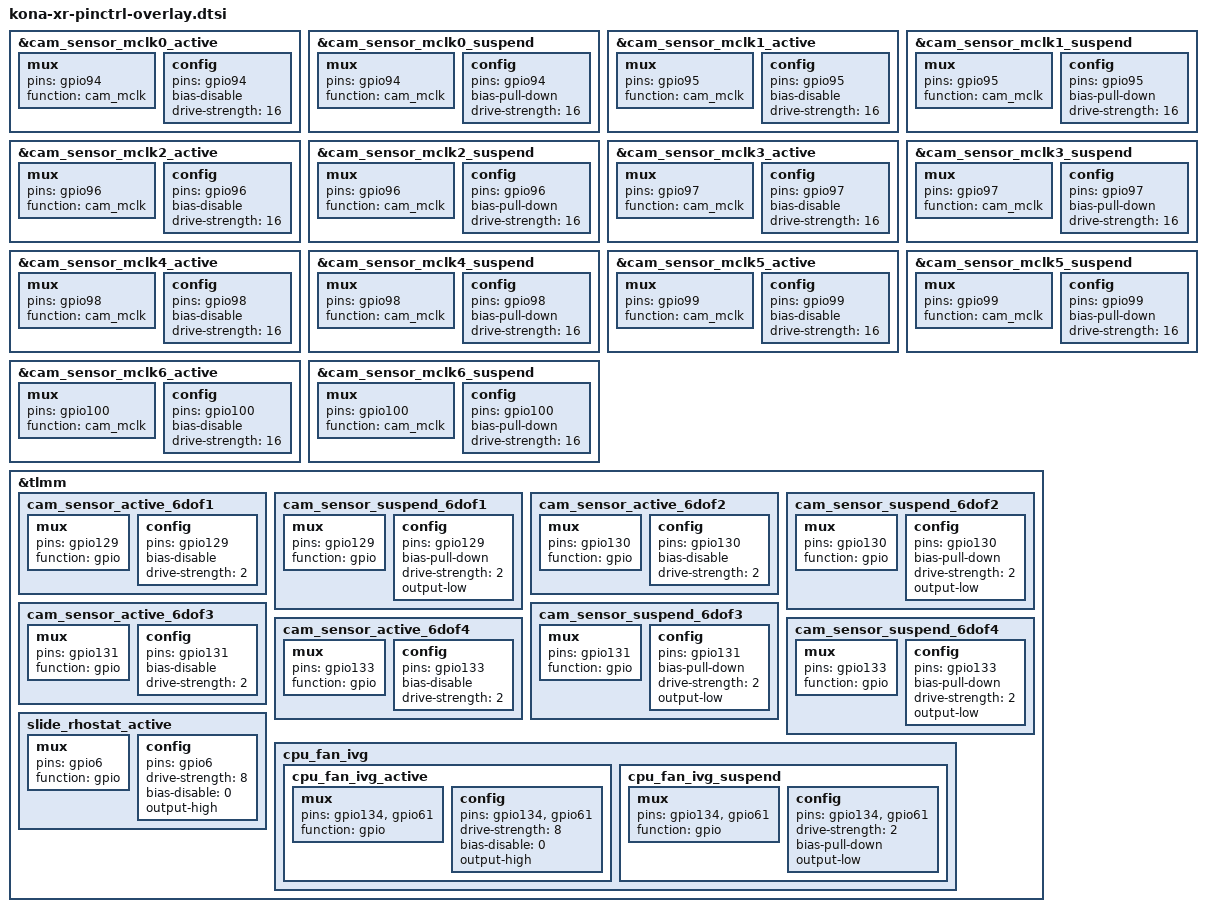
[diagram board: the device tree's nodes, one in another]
&cam_sensor_mclk0_active {
	/* MCLK0 */
	mux {
		pins = "gpio94";
		function = "cam_mclk";
	};

	config {
		pins = "gpio94";
		bias-disable; /* No PULL */
		drive-strength = <16>; /* 2 MA */
	};
};

&cam_sensor_mclk0_suspend {
	/* MCLK0 */
	mux {
		pins = "gpio94";
		function = "cam_mclk";
	};

	config {
		pins = "gpio94";
	bias-pull-down; /* PULL DOWN */
	drive-strength = <16>; /* 2 MA */
	};
};

&cam_sensor_mclk1_active {
	/* MCLK1 */
	mux {
		pins = "gpio95";
		function = "cam_mclk";
	};

	config {
		pins = "gpio95";
		bias-disable; /* No PULL */
		drive-strength = <16>; /* 2 MA */
	};
};

&cam_sensor_mclk1_suspend {
	/* MCLK1 */
	mux {
		pins = "gpio95";
		function = "cam_mclk";
	};

	config {
		pins = "gpio95";
		bias-pull-down; /* PULL DOWN */
		drive-strength = <16>; /* 2 MA */
	};
};

&cam_sensor_mclk2_active {
	/* MCLK2 */
	mux {
		pins = "gpio96";
		function = "cam_mclk";
	};

	config {
		pins = "gpio96";
		bias-disable; /* No PULL */
		drive-strength = <16>; /* 2 MA */
	};
};

&cam_sensor_mclk2_suspend {
	/* MCLK2 */
	mux {
		pins = "gpio96";
		function = "cam_mclk";
	};

	config {
		pins = "gpio96";
		bias-pull-down; /* PULL DOWN */
		drive-strength = <16>; /* 2 MA */
	};
};

&cam_sensor_mclk3_active {
	/* MCLK3 */
	mux {
		pins = "gpio97";
		function = "cam_mclk";
	};

	config {
		pins = "gpio97";
		bias-disable; /* No PULL */
		drive-strength = <16>; /* 2 MA */
	};
};

&cam_sensor_mclk3_suspend {
	/* MCLK3 */
	mux {
		pins = "gpio97";
		function = "cam_mclk";
	};

	config {
		pins = "gpio97";
		bias-pull-down; /* PULL DOWN */
		drive-strength = <16>; /* 2 MA */
	};
};

&cam_sensor_mclk4_active {
	/* MCLK4 */
	mux {
		pins = "gpio98";
		function = "cam_mclk";
	};

	config {
		pins = "gpio98";
	bias-disable; /* No PULL */
	drive-strength = <16>; /* 2 MA */
	};
};

&cam_sensor_mclk4_suspend {
	/* MCLK4 */
	mux {
		pins = "gpio98";
		function = "cam_mclk";
	};

	config {
		pins = "gpio98";
		bias-pull-down; /* PULL DOWN */
		drive-strength = <16>; /* 2 MA */
	};
};

&cam_sensor_mclk5_active {
	/* MCLK5 */
	mux {
		pins = "gpio99";
		function = "cam_mclk";
	};

	config {
		pins = "gpio99";
		bias-disable; /* No PULL */
		drive-strength = <16>; /* 2 MA */
	};
};

&cam_sensor_mclk5_suspend {
	/* MCLK5 */
	mux {
		pins = "gpio99";
		function = "cam_mclk";
	};

	config {
		pins = "gpio99";
		bias-pull-down; /* PULL DOWN */
		drive-strength = <16>; /* 2 MA */
	};
};

&cam_sensor_mclk6_active {
	/* MCLK6 */
	mux {
		pins = "gpio100";
		function = "cam_mclk";
	};

	config {
		pins = "gpio100";
		bias-disable; /* No PULL */
		drive-strength = <16>; /* 2 MA */
	};
};

&cam_sensor_mclk6_suspend {
	/* MCLK6 */
	mux {
		pins = "gpio100";
		function = "cam_mclk";
	};

	config {
		pins = "gpio100";
		bias-pull-down; /* PULL DOWN */
		drive-strength = <16>; /* 2 MA */
	};
};

&tlmm{
	cam_sensor_active_6dof1: cam_sensor_active_6dof1 {
	    mux {
	        pins = "gpio129";
	        function = "gpio";
	    };
	    config {
	        pins = "gpio129";
	        bias-disable; /* No PULL */
	        drive-strength = <2>; /* 2 MA */
	    };
	};

	cam_sensor_suspend_6dof1: cam_sensor_suspend_6dof1 {
	    mux {
	        pins = "gpio129";
	        function = "gpio";
	    };
	    config {
	        pins = "gpio129";
	        bias-pull-down; /* PULL DOWN */
	        drive-strength = <2>; /* 2 MA */
	        output-low;
	    };
	};

	cam_sensor_active_6dof2: cam_sensor_active_6dof2 {
	    mux {
	        pins = "gpio130";
	        function = "gpio";
	    };
	    config {
	        pins = "gpio130";
	        bias-disable;
	        drive-strength = <2>;
	    };
	};

	cam_sensor_suspend_6dof2: cam_sensor_suspend_6dof2 {
	    mux {
	        pins = "gpio130";
	        function = "gpio";
	    };
	    config {
	        pins = "gpio130";
	        bias-pull-down;
	        drive-strength = <2>;
	        output-low;
	    };
	};

	cam_sensor_active_6dof3: cam_sensor_active_6dof3 {
	    mux {
	        pins = "gpio131";
	        function = "gpio";
	    };
	    config {
	        pins = "gpio131";
	        bias-disable; /* No PULL */
	        drive-strength = <2>; /* 2 MA */
	    };
	};

	cam_sensor_suspend_6dof3: cam_sensor_suspend_6dof3 {
	    mux {
	        pins = "gpio131";
	        function = "gpio";
	    };

	    config {
	        pins = "gpio131";
	        bias-pull-down; /* PULL DOWN */
	        drive-strength = <2>; /* 2 MA */
	        output-low;
	    };
	};

	cam_sensor_active_6dof4: cam_sensor_active_6dof4 {
	    mux {
	        pins = "gpio133";
	        function = "gpio";
	    };

	    config {
	        pins = "gpio133";
	        bias-disable;
	        drive-strength = <2>;
	    };
	};

	cam_sensor_suspend_6dof4: cam_sensor_suspend_6dof4 {
	    mux {
	        pins = "gpio133";
	        function = "gpio";
	    };
	    config {
	        pins = "gpio133";
	        bias-pull-down;
	        drive-strength = <2>;
	        output-low;
	    };
	};
};

&tlmm {
	slide_rhostat_active: slide_rhostat_active {
		mux {
			pins = "gpio6";
			function = "gpio";
		};

		config {
			pins = "gpio6";
			drive-strength = <8>;
			bias-disable = <0>;
			output-high;
		};
	};
};

&tlmm {
	cpu_fan_ivg: cpu_fan_ivg {
		cpu_fan_ivg_active:cpu_fan_ivg_active {
			mux {
				pins = "gpio134","gpio61";
				function = "gpio";
			};

			config {
				pins = "gpio134","gpio61";
				drive-strength = <8>;
				bias-disable = <0>;
				output-high;
			};
		};
		cpu_fan_ivg_suspend: cpu_fan_ivg_suspend {
			mux {
				pins = "gpio134","gpio61";
				function = "gpio";
			};

			config {
				pins = "gpio134","gpio61";
				drive-strength = <2>;
				bias-pull-down;
				output-low;
			};
		};
	};
};

